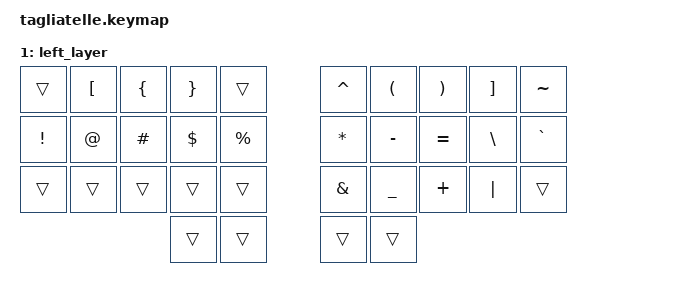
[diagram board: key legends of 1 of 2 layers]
// Copyright (c) 2022 The ZMK Contributors
// SPDX-License-Identifier: MIT

#include <behaviors.dtsi>
#include <dt-bindings/zmk/keys.h>
#include <dt-bindings/zmk/bt.h>

// Home row mods macro
#define HRML(k1,k2,k3,k4) &ht LSHFT k1  &ht LALT k2  &ht LCTRL k3  &ht LGUI k4
#define HRMR(k1,k2,k3,k4) &ht RGUI k1  &ht RCTRL k2  &ht RALT k3  &ht RSHFT k4
#define DEFAULT 0
#define NUM 1

/ {
    behaviors {
        ht: hold_tap {
            compatible = "zmk,behavior-hold-tap";
            #binding-cells = <2>;
            flavor = "tap-preferred";
            tapping-term-ms = <220>;
            quick-tap-ms = <150>;
            require-prior-idle-ms = <100>;
            bindings = <&kp>, <&kp>;
        };
    };

    conditional_layers {
        compatible = "zmk,conditional-layers";
        tri_layer {
            if-layers = <1 2>;
            then-layer = <3>;
        };
    };

    keymap {
        compatible = "zmk,keymap";
        default_layer {
            bindings = <
        //╭──────────┬──────────┬──────────┬──────────┬──────────╮   ╭──────────┬──────────┬──────────┬──────────┬──────────╮
        //│  Q       │  W       │  E       │  R       │  T       │   │  Y       │  U       │  I       │  O       │  P       │
            &kp W      &kp L      &kp R      &kp B      &kp Z          &kp SQT     &kp Q      &kp U      &kp D      &kp J
        //├──────────┼──────────┼──────────┼──────────┼──────────┤   ├──────────┼──────────┼──────────┼──────────┼──────────┤
        //│  A       │  S       │  D       │  F       │  G       │   │  H       │  J       │  K       │  L       │ ' "      │
            HRML(S,        H,         N,         T)     &kp COMMA       &kp DOT     HRMR(A,        E,         O,        I)
        //├──────────┼──────────┼──────────┼──────────┼──────────┤   ├──────────┼──────────┼──────────┼──────────┼──────────┤
        //│  Z       │  X       │  C       │  V       │  B       │   │  N       │  M       │ , <      │ . >      │ / ?      │
            &kp F      &kp M      &kp V      &kp C      &trans       &kp G      &kp P      &kp X      &kp K    &kp Y
        //╰──────────┴──────────┴──────────┼──────────┼──────────┤   ├──────────┼──────────┼──────────┴──────────┴──────────╯
                                            &mo NUM     &kp ENTER     &kp BSPC  &kp 1 SPACE
        //                                 ╰──────────┴──────────╯   ╰──────────┴──────────╯
            >;
        };

        left_layer {
            bindings = <
        //╭──────────┬──────────┬──────────┬──────────┬──────────╮   ╭──────────┬──────────┬──────────┬──────────┬──────────╮
        //│          │  [       │  {       │  }       │          │   │  ^       │  (       │  )       │  ]       │  ~       │
            &trans     &trans       &trans    &trans     &trans         &trans      &kp N7      &KP N8  &KP N9     &trans
        //├──────────┼──────────┼──────────┼──────────┼──────────┤   ├──────────┼──────────┼──────────┼──────────┼──────────┤
        //│  !       │  @       │  #       │  $       │  %       │   │  *       │  -       │  =       │  \       │  `       │
            &trans      &trans      &trans    &kp N0     &trans         &trans     &kp N3     &kp N4     &kp N5   &trans
        //├──────────┼──────────┼──────────┼──────────┼──────────┤   ├──────────┼──────────┼──────────┼──────────┼──────────┤
        //│          │          │          │          │          │   │  &       │  _       │  +       │  │       │          │
            &trans     &trans     &trans     &trans     &trans         &trans      &kp N1      &kp N2   &kp N3     &trans
        //╰──────────┴──────────┴──────────┼──────────┼──────────┤   ├──────────┼──────────┼──────────┴──────────┴──────────╯
                                             &trans     &trans         &trans     &trans
        //                                 ╰──────────┴──────────╯   ╰──────────┴──────────╯
            >;
        };
       
        left_layer {
            bindings = <
        //╭──────────┬──────────┬──────────┬──────────┬──────────╮   ╭──────────┬──────────┬──────────┬──────────┬──────────╮
        //│          │  [       │  {       │  }       │          │   │  ^       │  (       │  )       │  ]       │  ~       │
            &trans     &kp LBKT   &kp LBRC   &kp RBRC   &trans         &kp CARET  &kp LPAR   &kp RPAR   &kp RBKT   &kp TILDE
        //├──────────┼──────────┼──────────┼──────────┼──────────┤   ├──────────┼──────────┼──────────┼──────────┼──────────┤
        //│  !       │  @       │  #       │  $       │  %       │   │  *       │  -       │  =       │  \       │  `       │
            &kp EXCL   &kp AT     &kp HASH   &kp DLLR   &kp PRCNT      &kp ASTRK  &kp MINUS  &kp EQUAL  &kp BSLH   &kp GRAVE
        //├──────────┼──────────┼──────────┼──────────┼──────────┤   ├──────────┼──────────┼──────────┼──────────┼──────────┤
        //│          │          │          │          │          │   │  &       │  _       │  +       │  │       │          │
            &trans     &trans     &trans     &trans     &trans         &kp AMPS   &kp UNDER  &kp PLUS   &kp PIPE   &trans
        //╰──────────┴──────────┴──────────┼──────────┼──────────┤   ├──────────┼──────────┼──────────┴──────────┴──────────╯
                                             &trans     &trans         &trans     &trans
        //                                 ╰──────────┴──────────╯   ╰──────────┴──────────╯
            >;
        };

    };
};
